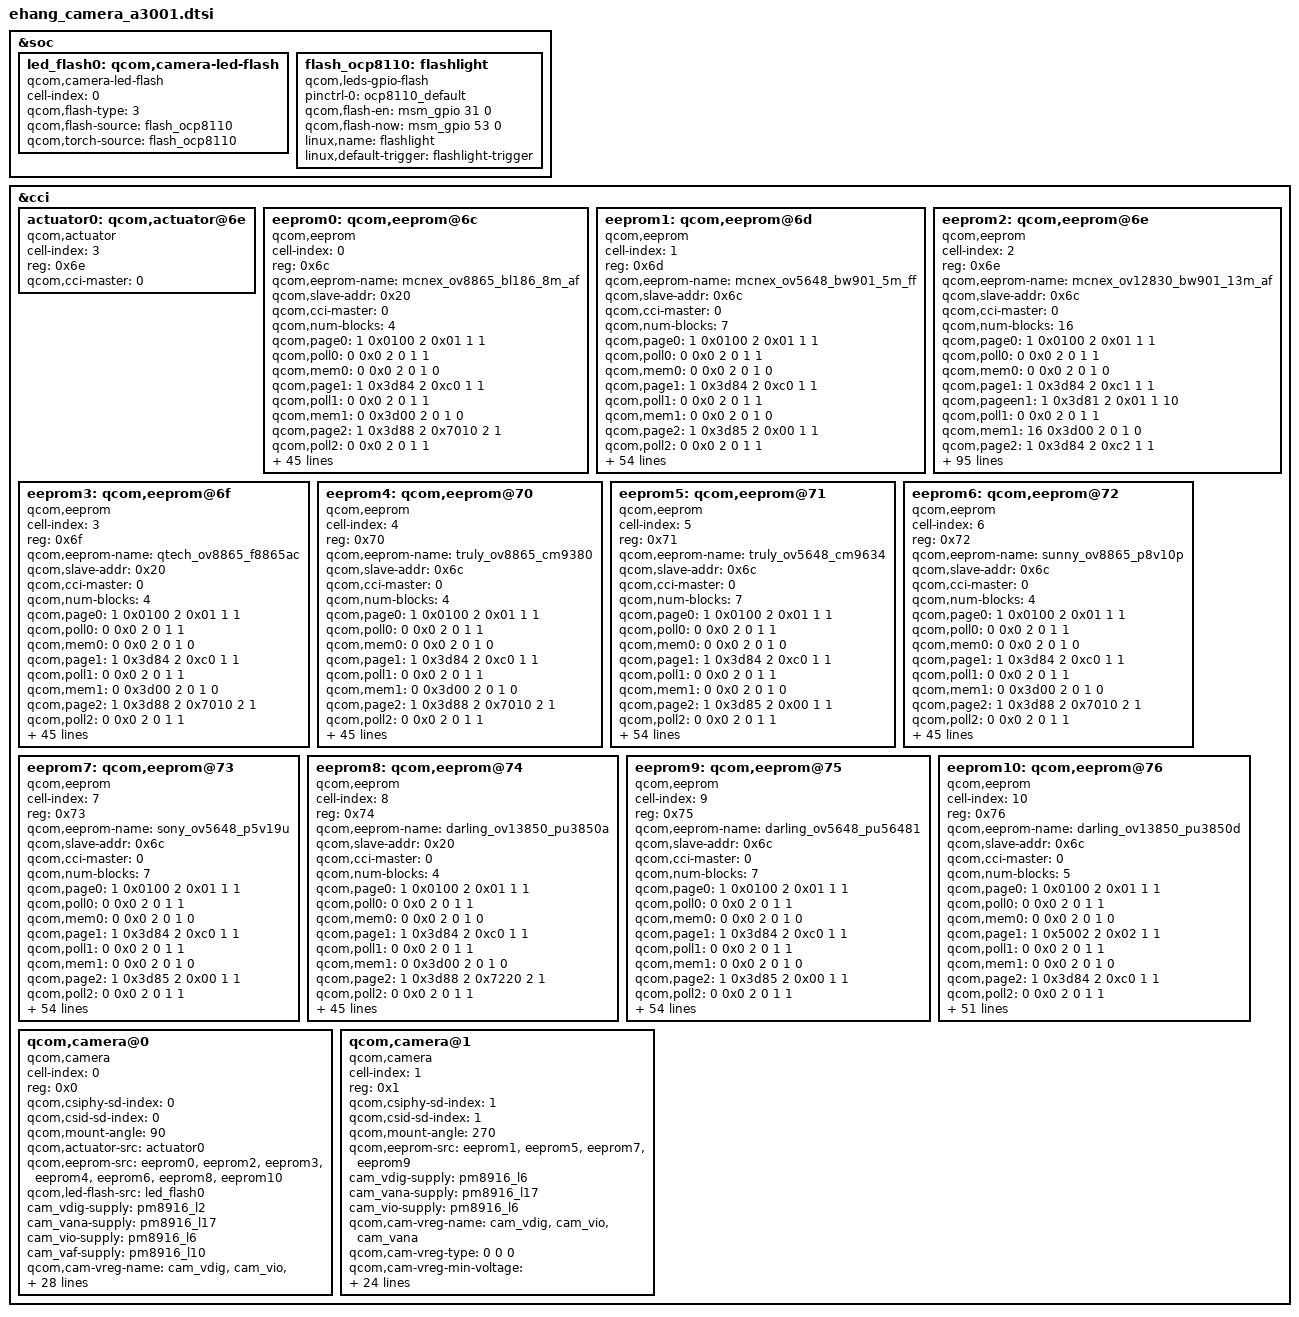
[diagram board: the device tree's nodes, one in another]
/*
 * Copyright (c) 2014, The Linux Foundation. All rights reserved.
 *
 * This program is free software; you can redistribute it and/or modify
 * it under the terms of the GNU General Public License version 2 and
 * only version 2 as published by the Free Software Foundation.
 *
 * This program is distributed in the hope that it will be useful,
 * but WITHOUT ANY WARRANTY; without even the implied warranty of
 * MERCHANTABILITY or FITNESS FOR A PARTICULAR PURPOSE.  See the
 * GNU General Public License for more details.
 */

&soc {
	/*
	i2c@78b9000 {
		led_flash0:sgm,led-flash@60 {
			cell-index = <0>;
			reg = <0x60>;
			compatible = "sgm,led-flash";
			label = "sgm3780";
			qcom,slave-id = <0x60 0x00 0x0011>;
			gpios = <&msm_gpio 31 0>,
			        <&msm_gpio 86 0>;
			qcom,gpio-flash-en = <0>;
			qcom,gpio-flash-now = <1>;
			qcom,gpio-req-tbl-num = <0 1>;
			qcom,gpio-req-tbl-flags = <0 0>;
			qcom,gpio-req-tbl-label = "FLASH_EN",
			                          "FLASH_NOW";					  
		};
	};*/	

	led_flash0: qcom,camera-led-flash {
		cell-index = <0>;
		compatible = "qcom,camera-led-flash";
		qcom,flash-type = <3>;
		qcom,flash-source = <&flash_ocp8110>;
		qcom,torch-source = <&flash_ocp8110>;
	};
	
	/*led_flash0: qcom,led-flash@0 {
		cell-index = <0>;
		reg = <0x66>;
		qcom,slave-id = <0x66 0x00 0x0011>;
		compatible = "qcom,led-flash1";
		label = "bd7710";
		qcom,flash-type = <1>;
		qcom,gpio-no-mux = <0>;
		qcom,enable_pinctrl;
		pinctrl-names = "cam_flash_default", "cam_flash_suspend";
		pinctrl-0 = <&cam_sensor_flash_default>;
		pinctrl-1 = <&cam_sensor_flash_sleep>;
		gpios = <&msm_gpio 36 0>,
			<&msm_gpio 32 0>,
			<&msm_gpio 31 0>;
		qcom,gpio-flash-reset = <0>;
		qcom,gpio-flash-en = <1>;
		qcom,gpio-flash-now = <2>;
		qcom,gpio-req-tbl-num = <0 1 2>;
		qcom,gpio-req-tbl-flags = <0 0 0>;
		qcom,gpio-req-tbl-label = "FLASH_RST",
			"FLASH_EN",
			"FLASH_NOW";
		qcom,cci-master = <0>;
	};*/
	
	flash_ocp8110:flashlight {
		compatible = "qcom,leds-gpio-flash";
		status = "okay";
		pinctrl-names = "ocp8110_default";
		pinctrl-0 = <&ocp8110_default>;
		qcom,flash-en = <&msm_gpio 31 0>;
		qcom,flash-now = <&msm_gpio 53 0>;
		linux,name = "flashlight";
		linux,default-trigger = "flashlight-trigger";
	};
};

&cci {

	actuator0: qcom,actuator@6e {
		cell-index = <3>;
		reg = <0x6e>;
		compatible = "qcom,actuator";
		qcom,cci-master = <0>;
	};
	
	eeprom0: qcom,eeprom@6c {
		cell-index = <0>;
		reg = <0x6c>;
		qcom,eeprom-name = "mcnex_ov8865_bl186_8m_af";
		compatible = "qcom,eeprom";
		qcom,slave-addr = <0x20>;
		qcom,cci-master = <0>;
		qcom,num-blocks = <4>;
		qcom,page0 = <1 0x0100 2 0x01 1 1>;
		qcom,poll0 = <0 0x0 2 0 1 1>;
		qcom,mem0 = <0 0x0 2 0 1 0>;
		qcom,page1 = <1 0x3d84 2 0xc0 1 1>;
		qcom,poll1 = <0 0x0 2 0 1 1>;
		qcom,mem1 = <0 0x3d00 2 0 1 0>;
		qcom,page2 = <1 0x3d88 2 0x7010 2 1>;
		qcom,poll2 = <0 0x0 2 0 1 1>;
		qcom,mem2 = <0 0x3d00 2 0 1 0>;
		qcom,page3 = <1 0x3d8A 2 0x70F4 2 1>;
		qcom,pageen3 = <1 0x3d81 2 0x01 1 10>;
		qcom,poll3 = <0 0x0 2 0 1 1>;
		qcom,mem3 = <228 0x7010 2 0 1 1>;
	
		cam_vdig-supply = <&pm8916_l2>;
		cam_vana-supply = <&pm8916_l17>;
		cam_vio-supply = <&pm8916_l6>;
		qcom,cam-vreg-name = "cam_vdig","cam_vana", "cam_vio";
		qcom,cam-vreg-type = <0 0 0>;
		qcom,cam-vreg-min-voltage = <1200000 2850000 1800000>;
		qcom,cam-vreg-max-voltage = <1200000 2850000 1800000>;
		qcom,cam-vreg-op-mode = <200000 80000 80000>;	
		pinctrl-names = "cam_default", "cam_suspend";
		pinctrl-0 = <&cam_sensor_mclk0_default
		             &cam_sensor_rear_default>;
		pinctrl-1 = <&cam_sensor_mclk0_sleep &cam_sensor_rear_sleep>;		
		qcom,gpio-no-mux = <0>;	
		gpios = <&msm_gpio 26 0>,
		        <&msm_gpio 35 0>,
		        <&msm_gpio 34 0>,
		        <&msm_gpio 121 0>;
		qcom,gpio-reset = <1>;
		qcom,gpio-standby = <2>;
		qcom,gpio-vana = <3>;
		qcom,gpio-req-tbl-num = <0 1 2 3>;
		qcom,gpio-req-tbl-flags = <1 0 0 0>;
		qcom,gpio-req-tbl-label = "CAMIF_MCLK",
					  "CAM_RESET",
					  "CAM_STANDBY",
					  "CAM_VANA";
		qcom,cam-power-seq-type = "sensor_vreg",
		                          "sensor_vreg",
					  "sensor_gpio",
					  "sensor_vreg",
					  "sensor_gpio",
					  "sensor_gpio",
					  "sensor_gpio",
					  "sensor_gpio",
					  "sensor_clk",		
					  "sensor_i2c_mux";
		qcom,cam-power-seq-val = "cam_vio",
		                         "cam_vana",
					 "sensor_gpio_vana",
					 "cam_vdig",
					 "sensor_gpio_standby",
					 "sensor_gpio_reset",
					 "sensor_gpio_standby",
					 "sensor_gpio_reset",
					 "sensor_cam_mclk",
					 "none";
		qcom,cam-power-seq-cfg-val = <0 0 1 0 0 0 1 1 23880000 0>;
		qcom,cam-power-seq-delay = <1 1 5 1 1 5 5 10 10 0>;
		clocks = <&clock_gcc clk_mclk0_clk_src>,
		         <&clock_gcc clk_gcc_camss_mclk0_clk>;
		clock-names = "cam_src_clk", "cam_clk";
	};
	eeprom1: qcom,eeprom@6d {
		cell-index = <1>;
		reg = <0x6d>;
		qcom,eeprom-name = "mcnex_ov5648_bw901_5m_ff";
		compatible = "qcom,eeprom";
		qcom,slave-addr = <0x6c>;
		qcom,cci-master = <0>;
		qcom,num-blocks = <7>;
		qcom,page0 = <1 0x0100 2 0x01 1 1>;
		qcom,poll0 = <0 0x0 2 0 1 1>;
		qcom,mem0 = <0 0x0 2 0 1 0>;
		qcom,page1 = <1 0x3d84 2 0xc0 1 1>;
		qcom,poll1 = <0 0x0 2 0 1 1>;
		qcom,mem1 = <0 0x0 2 0 1 0>;
		qcom,page2 = <1 0x3d85 2 0x00 1 1>;
		qcom,poll2 = <0 0x0 2 0 1 1>;
		qcom,mem2 = <0 0x0 2 0 1 0>;
		qcom,page3 = <1 0x3d86 2 0x0f 1 1>;
		qcom,pageen3 = <1 0x3d81 2 0x01 1 10>;
		qcom,poll3 = <0 0x0 2 0 1 1>;
		qcom,mem3 = <16 0x3d00 2 0 1 0>;
		qcom,page4 = <1 0x3d84 2 0xc0 1 1>;
		qcom,poll4 = <0 0x0 2 0 1 1>;
		qcom,mem4 = <0 0x0 2 0 1 0>;
		qcom,page5 = <1 0x3d85 2 0x10 1 1>;
		qcom,poll5 = <0 0x0 2 0 1 1>;
		qcom,mem5 = <0 0x0 2 0 1 0>;
		qcom,page6 = <1 0x3d86 2 0x1f 1 1>;
		qcom,pageen6 = <1 0x3d81 2 0x01 1 10>;
		qcom,poll6 = <0 0x0 2 0 1 1>;
		qcom,mem6 = <16 0x3d00 2 0 1 0>;	
		cam_vdig-supply = <&pm8916_l6>;
		cam_vana-supply = <&pm8916_l17>;
		cam_vio-supply = <&pm8916_l6>;
		qcom,cam-vreg-name = "cam_vdig","cam_vio", "cam_vana";
		qcom,cam-vreg-type = <0 0 0>;
		qcom,cam-vreg-min-voltage = <1800000 1800000 2850000>;
		qcom,cam-vreg-max-voltage = <1800000 1800000 2850000>;
		qcom,cam-vreg-op-mode = <150000 150000 150000>;	
		pinctrl-names = "cam_default", "cam_suspend";
		pinctrl-0 = <&cam_sensor_mclk1_default &cam_sensor_front_default>;
		pinctrl-1 = <&cam_sensor_mclk1_sleep &cam_sensor_front_sleep>;
		
		gpios = <&msm_gpio 27 0>,
			<&msm_gpio 28 0>,
			<&msm_gpio 33 0>,			
			<&msm_gpio 121 0>;
		qcom,gpio-reset = <1>;
		qcom,gpio-standby = <2>;		
		qcom,gpio-vana = <3>;			
		qcom,gpio-req-tbl-num = <0 1 2 3>;
		qcom,gpio-req-tbl-flags = <1 0 0 0>;
		qcom,gpio-req-tbl-label = "CAMIF_MCLK",
			                  "CAM_RESET",
			                  "CAM_STANDBY",	
			                  "CAM_VANA";			
		qcom,cam-power-seq-type = "sensor_vreg",
		                          "sensor_vreg",
					  "sensor_gpio",
					  "sensor_vreg",
					  "sensor_gpio",
					  "sensor_gpio",
					  "sensor_gpio",
					  "sensor_gpio",
					  "sensor_clk",		
					  "sensor_i2c_mux";
		qcom,cam-power-seq-val =  "cam_vio",
		                          "cam_vana",
					  "sensor_gpio_vana",
					  "cam_vdig",
					  "sensor_gpio_standby",
					  "sensor_gpio_reset",
					  "sensor_gpio_standby",
					  "sensor_gpio_reset",
					  "sensor_cam_mclk",
					  "none";
		qcom,cam-power-seq-cfg-val = <0 0 1 0 0 0 1 1 23880000 0>;
		qcom,cam-power-seq-delay = <1 1 5 1 1 5 5 10 10 0>;
		clocks = <&clock_gcc clk_mclk1_clk_src>,
		         <&clock_gcc clk_gcc_camss_mclk1_clk>;
		clock-names = "cam_src_clk", "cam_clk";
	};
	eeprom2: qcom,eeprom@6e{
		cell-index = <2>;
		reg = <0x6e>;
		qcom,eeprom-name = "mcnex_ov12830_bw901_13m_af";
		compatible = "qcom,eeprom";
		qcom,slave-addr = <0x6c>;
		qcom,cci-master = <0>;
		qcom,num-blocks = <16>;
		qcom,page0 = <1 0x0100 2 0x01 1 1>;
		qcom,poll0 = <0 0x0 2 0 1 1>;
		qcom,mem0 = <0 0x0 2 0 1 0>;
		qcom,page1 = <1 0x3d84 2 0xc1 1 1>;
		qcom,pageen1 = <1 0x3d81 2 0x01 1 10>;
		qcom,poll1 = <0 0x0 2 0 1 1>;
		qcom,mem1 = <16 0x3d00 2 0 1 0>;
		qcom,page2 = <1 0x3d84 2 0xc2 1 1>;
		qcom,pageen2 = <1 0x3d81 2 0x01 1 10>;
		qcom,poll2 = <0 0x0 2 0 1 1>;
		qcom,mem2 = <16 0x3d00 2 0 1 0>;
		qcom,page3 = <1 0x3d84 2 0xc3 1 1>;
		qcom,pageen3 = <1 0x3d81 2 0x01 1 10>;
		qcom,poll3 = <0 0x0 2 0 1 1>;
		qcom,mem3 = <16 0x3d00 2 0 1 0>;
		qcom,page4 = <1 0x3d84 2 0xc4 1 1>;
		qcom,pageen4 = <1 0x3d81 2 0x01 1 10>;
		qcom,poll4 = <0 0x0 2 0 1 1>;
		qcom,mem4 = <16 0x3d00 2 0 1 0>;
		qcom,page5 = <1 0x3d84 2 0xc5 1 1>;
		qcom,pageen5 = <1 0x3d81 2 0x01 1 10>;
		qcom,poll5 = <0 0x0 2 0 1 1>;
		qcom,mem5 = <16 0x3d00 2 0 1 0>;
		qcom,page6 = <1 0x3d84 2 0xc6 1 1>;
		qcom,pageen6 = <1 0x3d81 2 0x01 1 10>;
		qcom,poll6 = <0 0x0 2 0 1 1>;
		qcom,mem6 = <16 0x3d00 2 0 1 0>;
		qcom,page7 = <1 0x3d84 2 0xc7 1 1>;
		qcom,pageen7 = <1 0x3d81 2 0x01 1 10>;
		qcom,poll7 = <0 0x0 2 0 1 1>;
		qcom,mem7 = <16 0x3d00 2 0 1 0>;
		qcom,page8 = <1 0x3d84 2 0xc8 1 1>;
		qcom,pageen8 = <1 0x3d81 2 0x01 1 10>;
		qcom,poll8 = <0 0x0 2 0 1 1>;
		qcom,mem8 = <16 0x3d00 2 0 1 0>;
		qcom,page9 = <1 0x3d84 2 0xc9 1 1>;
		qcom,pageen9 = <1 0x3d81 2 0x01 1 10>;
		qcom,poll9 = <0 0x0 2 0 1 1>;
		qcom,mem9 = <16 0x3d00 2 0 1 0>;
		qcom,page10 = <1 0x3d84 2 0xca 1 1>;
		qcom,pageen10 = <1 0x3d81 2 0x01 1 10>;
		qcom,poll10 = <0 0x0 2 0 1 1>;
		qcom,mem10 = <16 0x3d00 2 0 1 0>;
		qcom,page11 = <1 0x3d84 2 0xcb 1 1>;
		qcom,pageen11 = <1 0x3d81 2 0x01 1 10>;
		qcom,poll11 = <0 0x0 2 0 1 1>;
		qcom,mem11 = <16 0x3d00 2 0 1 0>;
		qcom,page12 = <1 0x3d84 2 0xcc 1 1>;
		qcom,pageen12 = <1 0x3d81 2 0x01 1 10>;
		qcom,poll12 = <0 0x0 2 0 1 1>;
		qcom,mem12 = <16 0x3d00 2 0 1 0>;
		qcom,page13 = <1 0x3d84 2 0xcd 1 1>;
		qcom,pageen13 = <1 0x3d81 2 0x01 1 10>;
		qcom,poll13 = <0 0x0 2 0 1 1>;
		qcom,mem13 = <16 0x3d00 2 0 1 0>;
		qcom,page14 = <1 0x3d84 2 0xce 1 1>;
		qcom,pageen14 = <1 0x3d81 2 0x01 1 10>;
		qcom,poll14 = <0 0x0 2 0 1 1>;
		qcom,mem14 = <16 0x3d00 2 0 1 0>;
		qcom,page15 = <1 0x3d84 2 0xcf 1 1>;
		qcom,pageen15 = <1 0x3d81 2 0x01 1 10>;
		qcom,poll15 = <0 0x0 2 0 1 1>;
		qcom,mem15 = <16 0x3d00 2 0 1 0>;	
		cam_vdig-supply = <&pm8916_l2>;
		cam_vana-supply = <&pm8916_l17>;
		cam_vio-supply = <&pm8916_l6>;
		qcom,cam-vreg-name = "cam_vdig","cam_vana", "cam_vio";
		qcom,cam-vreg-type = <0 0 0>;
		qcom,cam-vreg-min-voltage = <1200000 2850000 1800000>;
		qcom,cam-vreg-max-voltage = <1200000 2850000 1800000>;
		qcom,cam-vreg-op-mode = <200000 80000 80000>;	
		pinctrl-names = "cam_default", "cam_suspend";
		pinctrl-0 = <&cam_sensor_mclk0_default
		             &cam_sensor_rear_default>;
		pinctrl-1 = <&cam_sensor_mclk0_sleep &cam_sensor_rear_sleep>;		
		qcom,gpio-no-mux = <0>;	
		gpios = <&msm_gpio 26 0>,
		        <&msm_gpio 35 0>,
		        <&msm_gpio 34 0>,
		        <&msm_gpio 121 0>;
		qcom,gpio-reset = <1>;
		qcom,gpio-standby = <2>;
		qcom,gpio-vana = <3>;
		qcom,gpio-req-tbl-num = <0 1 2 3>;
		qcom,gpio-req-tbl-flags = <1 0 0 0>;
		qcom,gpio-req-tbl-label = "CAMIF_MCLK",
					  "CAM_RESET",
					  "CAM_STANDBY",
					  "CAM_VANA";
		qcom,cam-power-seq-type = "sensor_vreg",
		                          "sensor_vreg",
					  "sensor_gpio",
					  "sensor_vreg",
					  "sensor_gpio",
					  "sensor_gpio",
					  "sensor_gpio",
					  "sensor_gpio",
					  "sensor_clk",		
					  "sensor_i2c_mux";
		qcom,cam-power-seq-val = "cam_vio",
		                         "cam_vana",
					 "sensor_gpio_vana",
					 "cam_vdig",
					 "sensor_gpio_standby",
					 "sensor_gpio_reset",
					 "sensor_gpio_standby",
					 "sensor_gpio_reset",
					 "sensor_cam_mclk",
					 "none";
		qcom,cam-power-seq-cfg-val = <0 0 1 0 0 0 1 1 23880000 0>;
		qcom,cam-power-seq-delay = <1 1 5 1 1 5 5 10 10 0>;
		clocks = <&clock_gcc clk_mclk0_clk_src>,
		         <&clock_gcc clk_gcc_camss_mclk0_clk>;
		clock-names = "cam_src_clk", "cam_clk";
	};
	
	eeprom3: qcom,eeprom@6f {
		cell-index = <3>;
		reg = <0x6f>;
		qcom,eeprom-name = "qtech_ov8865_f8865ac";
		compatible = "qcom,eeprom";
		qcom,slave-addr = <0x20>;
		qcom,cci-master = <0>;
		qcom,num-blocks = <4>;
		qcom,page0 = <1 0x0100 2 0x01 1 1>;
		qcom,poll0 = <0 0x0 2 0 1 1>;
		qcom,mem0 = <0 0x0 2 0 1 0>;
		qcom,page1 = <1 0x3d84 2 0xc0 1 1>;
		qcom,poll1 = <0 0x0 2 0 1 1>;
		qcom,mem1 = <0 0x3d00 2 0 1 0>;
		qcom,page2 = <1 0x3d88 2 0x7010 2 1>;
		qcom,poll2 = <0 0x0 2 0 1 1>;
		qcom,mem2 = <0 0x3d00 2 0 1 0>;
		qcom,page3 = <1 0x3d8A 2 0x70F4 2 1>;
		qcom,pageen3 = <1 0x3d81 2 0x01 1 10>;
		qcom,poll3 = <0 0x0 2 0 1 1>;
		qcom,mem3 = <228 0x7010 2 0 1 1>;
	
		cam_vdig-supply = <&pm8916_l2>;
		cam_vana-supply = <&pm8916_l17>;
		cam_vio-supply = <&pm8916_l6>;
		qcom,cam-vreg-name = "cam_vdig","cam_vana", "cam_vio";
		qcom,cam-vreg-type = <0 0 0>;
		qcom,cam-vreg-min-voltage = <1200000 2850000 1800000>;
		qcom,cam-vreg-max-voltage = <1200000 2850000 1800000>;
		qcom,cam-vreg-op-mode = <200000 80000 80000>;	
		pinctrl-names = "cam_default", "cam_suspend";
		pinctrl-0 = <&cam_sensor_mclk0_default
		             &cam_sensor_rear_default>;
		pinctrl-1 = <&cam_sensor_mclk0_sleep &cam_sensor_rear_sleep>;		
		qcom,gpio-no-mux = <0>;	
		gpios = <&msm_gpio 26 0>,
		        <&msm_gpio 35 0>,
		        <&msm_gpio 34 0>,
		        <&msm_gpio 121 0>;
		qcom,gpio-reset = <1>;
		qcom,gpio-standby = <2>;
		qcom,gpio-vana = <3>;
		qcom,gpio-req-tbl-num = <0 1 2 3>;
		qcom,gpio-req-tbl-flags = <1 0 0 0>;
		qcom,gpio-req-tbl-label = "CAMIF_MCLK",
					  "CAM_RESET",
					  "CAM_STANDBY",
					  "CAM_VANA";
		qcom,cam-power-seq-type = "sensor_vreg",
		                          "sensor_vreg",
					  "sensor_gpio",
					  "sensor_vreg",
					  "sensor_gpio",
					  "sensor_gpio",
					  "sensor_gpio",
					  "sensor_gpio",
					  "sensor_clk",		
					  "sensor_i2c_mux";
		qcom,cam-power-seq-val = "cam_vio",
		                         "cam_vana",
					 "sensor_gpio_vana",
					 "cam_vdig",
					 "sensor_gpio_standby",
					 "sensor_gpio_reset",
					 "sensor_gpio_standby",
					 "sensor_gpio_reset",
					 "sensor_cam_mclk",
					 "none";
		qcom,cam-power-seq-cfg-val = <0 0 1 0 0 0 1 1 23880000 0>;   
		qcom,cam-power-seq-delay = <1 1 5 1 1 5 5 10 10 0>;
		clocks = <&clock_gcc clk_mclk0_clk_src>,
		         <&clock_gcc clk_gcc_camss_mclk0_clk>;
		clock-names = "cam_src_clk", "cam_clk";
	};
	eeprom4: qcom,eeprom@70 {
		cell-index = <4>;
		reg = <0x70>;
		qcom,eeprom-name = "truly_ov8865_cm9380";
		compatible = "qcom,eeprom";
		qcom,slave-addr = <0x6c>;	    
		qcom,cci-master = <0>;
		qcom,num-blocks = <4>;
		qcom,page0 = <1 0x0100 2 0x01 1 1>;
		qcom,poll0 = <0 0x0 2 0 1 1>;
		qcom,mem0 = <0 0x0 2 0 1 0>;
		qcom,page1 = <1 0x3d84 2 0xc0 1 1>;
		qcom,poll1 = <0 0x0 2 0 1 1>;
		qcom,mem1 = <0 0x3d00 2 0 1 0>;
		qcom,page2 = <1 0x3d88 2 0x7010 2 1>;
		qcom,poll2 = <0 0x0 2 0 1 1>;
		qcom,mem2 = <0 0x3d00 2 0 1 0>;
		qcom,page3 = <1 0x3d8A 2 0x70F4 2 1>;
		qcom,pageen3 = <1 0x3d81 2 0x01 1 10>;
		qcom,poll3 = <0 0x0 2 0 1 1>;
		qcom,mem3 = <228 0x7010 2 0 1 1>;		
		cam_vdig-supply = <&pm8916_l2>;
		cam_vana-supply = <&pm8916_l17>;
		cam_vio-supply = <&pm8916_l6>;
		qcom,cam-vreg-name = "cam_vdig","cam_vana", "cam_vio";
		qcom,cam-vreg-type = <0 0 0>;
		qcom,cam-vreg-min-voltage = <1200000 2850000 1800000>;
		qcom,cam-vreg-max-voltage = <1200000 2850000 1800000>;
		qcom,cam-vreg-op-mode = <200000 80000 80000>;	
		pinctrl-names = "cam_default", "cam_suspend";
		pinctrl-0 = <&cam_sensor_mclk0_default
		             &cam_sensor_rear_default>;
		pinctrl-1 = <&cam_sensor_mclk0_sleep &cam_sensor_rear_sleep>;		
		qcom,gpio-no-mux = <0>;	
		gpios = <&msm_gpio 26 0>,
		        <&msm_gpio 35 0>,
		        <&msm_gpio 34 0>,
		        <&msm_gpio 121 0>;
		qcom,gpio-reset = <1>;
		qcom,gpio-standby = <2>;
		qcom,gpio-vana = <3>;
		qcom,gpio-req-tbl-num = <0 1 2 3>;
		qcom,gpio-req-tbl-flags = <1 0 0 0>;
		qcom,gpio-req-tbl-label = "CAMIF_MCLK",
					  "CAM_RESET",
					  "CAM_STANDBY",
					  "CAM_VANA";
		qcom,cam-power-seq-type = "sensor_vreg",
		                          "sensor_vreg",
					  "sensor_gpio",
					  "sensor_vreg",
					  "sensor_gpio",
					  "sensor_gpio",
					  "sensor_gpio",
					  "sensor_gpio",
					  "sensor_clk",		
					  "sensor_i2c_mux";
		qcom,cam-power-seq-val = "cam_vio",
		                         "cam_vana",
					 "sensor_gpio_vana",
					 "cam_vdig",
					 "sensor_gpio_standby",
					 "sensor_gpio_reset",
					 "sensor_gpio_standby",
					 "sensor_gpio_reset",
					 "sensor_cam_mclk",
					 "none";
		qcom,cam-power-seq-cfg-val = <0 0 1 0 0 0 1 1 23880000 0>;
		qcom,cam-power-seq-delay = <1 1 5 1 1 5 5 10 10 0>;
		clocks = <&clock_gcc clk_mclk0_clk_src>,
		         <&clock_gcc clk_gcc_camss_mclk0_clk>;
		clock-names = "cam_src_clk", "cam_clk";
	};
	eeprom5: qcom,eeprom@71 {
		cell-index = <5>;
		reg = <0x71>;
		qcom,eeprom-name = "truly_ov5648_cm9634";
		compatible = "qcom,eeprom";
		qcom,slave-addr = <0x6c>;
		qcom,cci-master = <0>;
		qcom,num-blocks = <7>;
		qcom,page0 = <1 0x0100 2 0x01 1 1>;
		qcom,poll0 = <0 0x0 2 0 1 1>;
		qcom,mem0 = <0 0x0 2 0 1 0>;
		qcom,page1 = <1 0x3d84 2 0xc0 1 1>;
		qcom,poll1 = <0 0x0 2 0 1 1>;
		qcom,mem1 = <0 0x0 2 0 1 0>;
		qcom,page2 = <1 0x3d85 2 0x00 1 1>;
		qcom,poll2 = <0 0x0 2 0 1 1>;
		qcom,mem2 = <0 0x0 2 0 1 0>;
		qcom,page3 = <1 0x3d86 2 0x0f 1 1>;
		qcom,pageen3 = <1 0x3d81 2 0x01 1 10>;
		qcom,poll3 = <0 0x0 2 0 1 1>;
		qcom,mem3 = <16 0x3d00 2 0 1 0>;
		qcom,page4 = <1 0x3d84 2 0xc0 1 1>;
		qcom,poll4 = <0 0x0 2 0 1 1>;
		qcom,mem4 = <0 0x0 2 0 1 0>;
		qcom,page5 = <1 0x3d85 2 0x10 1 1>;
		qcom,poll5 = <0 0x0 2 0 1 1>;
		qcom,mem5 = <0 0x0 2 0 1 0>;
		qcom,page6 = <1 0x3d86 2 0x1f 1 1>;
		qcom,pageen6 = <1 0x3d81 2 0x01 1 10>;
		qcom,poll6 = <0 0x0 2 0 1 1>;
		qcom,mem6 = <16 0x3d00 2 0 1 0>;
		cam_vdig-supply = <&pm8916_l6>;
		cam_vana-supply = <&pm8916_l17>;
		cam_vio-supply = <&pm8916_l6>;
		qcom,cam-vreg-name = "cam_vdig","cam_vio", "cam_vana";
		qcom,cam-vreg-type = <0 0 0>;
		qcom,cam-vreg-min-voltage = <1800000 1800000 2850000>;
		qcom,cam-vreg-max-voltage = <1800000 1800000 2850000>;
		qcom,cam-vreg-op-mode = <150000 150000 150000>;	
		pinctrl-names = "cam_default", "cam_suspend";
		pinctrl-0 = <&cam_sensor_mclk1_default &cam_sensor_front_default>;
		pinctrl-1 = <&cam_sensor_mclk1_sleep &cam_sensor_front_sleep>;
		
		gpios = <&msm_gpio 27 0>,
			<&msm_gpio 28 0>,
			<&msm_gpio 33 0>,			
			<&msm_gpio 121 0>;
		qcom,gpio-reset = <1>;
		qcom,gpio-standby = <2>;		
		qcom,gpio-vana = <3>;			
		qcom,gpio-req-tbl-num = <0 1 2 3>;
		qcom,gpio-req-tbl-flags = <1 0 0 0>;
		qcom,gpio-req-tbl-label = "CAMIF_MCLK",
			                  "CAM_RESET",
			                  "CAM_STANDBY",	
			                  "CAM_VANA";			
		qcom,cam-power-seq-type = "sensor_vreg",
		                          "sensor_vreg",
					  "sensor_gpio",
					  "sensor_vreg",
					  "sensor_gpio",
					  "sensor_gpio",
					  "sensor_gpio",
					  "sensor_gpio",
					  "sensor_clk",		
					  "sensor_i2c_mux";
		qcom,cam-power-seq-val =  "cam_vio",
		                          "cam_vana",
					  "sensor_gpio_vana",
					  "cam_vdig",
					  "sensor_gpio_standby",
					  "sensor_gpio_reset",
					  "sensor_gpio_standby",
					  "sensor_gpio_reset",
					  "sensor_cam_mclk",
					  "none";
		qcom,cam-power-seq-cfg-val = <0 0 1 0 0 0 1 1 23880000 0>;
		qcom,cam-power-seq-delay = <1 1 5 1 1 5 5 10 10 0>;
		clocks = <&clock_gcc clk_mclk1_clk_src>,
		         <&clock_gcc clk_gcc_camss_mclk1_clk>;
		clock-names = "cam_src_clk", "cam_clk";
	};
	eeprom6: qcom,eeprom@72 {
		cell-index = <6>;
		reg = <0x72>;
		qcom,eeprom-name = "sunny_ov8865_p8v10p";
		compatible = "qcom,eeprom";
		qcom,slave-addr = <0x6c>;	    
		qcom,cci-master = <0>;
		qcom,num-blocks = <4>;
		qcom,page0 = <1 0x0100 2 0x01 1 1>;
		qcom,poll0 = <0 0x0 2 0 1 1>;
		qcom,mem0 = <0 0x0 2 0 1 0>;
		qcom,page1 = <1 0x3d84 2 0xc0 1 1>;
		qcom,poll1 = <0 0x0 2 0 1 1>;
		qcom,mem1 = <0 0x3d00 2 0 1 0>;
		qcom,page2 = <1 0x3d88 2 0x7010 2 1>;
		qcom,poll2 = <0 0x0 2 0 1 1>;
		qcom,mem2 = <0 0x3d00 2 0 1 0>;
		qcom,page3 = <1 0x3d8A 2 0x70F4 2 1>;
		qcom,pageen3 = <1 0x3d81 2 0x01 1 10>;
		qcom,poll3 = <0 0x0 2 0 1 1>;
		qcom,mem3 = <228 0x7010 2 0 1 1>;		
		cam_vdig-supply = <&pm8916_l2>;
		cam_vana-supply = <&pm8916_l17>;
		cam_vio-supply = <&pm8916_l6>;
		qcom,cam-vreg-name = "cam_vdig","cam_vana", "cam_vio";
		qcom,cam-vreg-type = <0 0 0>;
		qcom,cam-vreg-min-voltage = <1200000 2850000 1800000>;
		qcom,cam-vreg-max-voltage = <1200000 2850000 1800000>;
		qcom,cam-vreg-op-mode = <200000 80000 80000>;	
		pinctrl-names = "cam_default", "cam_suspend";
		pinctrl-0 = <&cam_sensor_mclk0_default
		             &cam_sensor_rear_default>;
		pinctrl-1 = <&cam_sensor_mclk0_sleep &cam_sensor_rear_sleep>;		
		qcom,gpio-no-mux = <0>;	
		gpios = <&msm_gpio 26 0>,
		        <&msm_gpio 35 0>,
		        <&msm_gpio 34 0>,
		        <&msm_gpio 121 0>;
		qcom,gpio-reset = <1>;
		qcom,gpio-standby = <2>;
		qcom,gpio-vana = <3>;
		qcom,gpio-req-tbl-num = <0 1 2 3>;
		qcom,gpio-req-tbl-flags = <1 0 0 0>;
		qcom,gpio-req-tbl-label = "CAMIF_MCLK",
					  "CAM_RESET",
					  "CAM_STANDBY",
					  "CAM_VANA";
		qcom,cam-power-seq-type = "sensor_vreg",
		                          "sensor_vreg",
					  "sensor_gpio",
					  "sensor_vreg",
					  "sensor_gpio",
					  "sensor_gpio",
					  "sensor_gpio",
					  "sensor_gpio",
					  "sensor_clk",		
					  "sensor_i2c_mux";
		qcom,cam-power-seq-val = "cam_vio",
		                         "cam_vana",
					 "sensor_gpio_vana",
					 "cam_vdig",
					 "sensor_gpio_standby",
					 "sensor_gpio_reset",
					 "sensor_gpio_standby",
					 "sensor_gpio_reset",
					 "sensor_cam_mclk",
					 "none";
		qcom,cam-power-seq-cfg-val = <0 0 1 0 0 0 1 1 23880000 0>;
		qcom,cam-power-seq-delay = <1 1 5 1 1 5 5 10 10 0>;
		clocks = <&clock_gcc clk_mclk0_clk_src>,
		         <&clock_gcc clk_gcc_camss_mclk0_clk>;
		clock-names = "cam_src_clk", "cam_clk";
	};
	eeprom7: qcom,eeprom@73 {
		cell-index = <7>;
		reg = <0x73>;
		qcom,eeprom-name = "sony_ov5648_p5v19u";
		compatible = "qcom,eeprom";
		qcom,slave-addr = <0x6c>;
		qcom,cci-master = <0>;
		qcom,num-blocks = <7>;
		qcom,page0 = <1 0x0100 2 0x01 1 1>;
		qcom,poll0 = <0 0x0 2 0 1 1>;
		qcom,mem0 = <0 0x0 2 0 1 0>;
		qcom,page1 = <1 0x3d84 2 0xc0 1 1>;
		qcom,poll1 = <0 0x0 2 0 1 1>;
		qcom,mem1 = <0 0x0 2 0 1 0>;
		qcom,page2 = <1 0x3d85 2 0x00 1 1>;
		qcom,poll2 = <0 0x0 2 0 1 1>;
		qcom,mem2 = <0 0x0 2 0 1 0>;
		qcom,page3 = <1 0x3d86 2 0x0f 1 1>;
		qcom,pageen3 = <1 0x3d81 2 0x01 1 10>;
		qcom,poll3 = <0 0x0 2 0 1 1>;
		qcom,mem3 = <16 0x3d00 2 0 1 0>;
		qcom,page4 = <1 0x3d84 2 0xc0 1 1>;
		qcom,poll4 = <0 0x0 2 0 1 1>;
		qcom,mem4 = <0 0x0 2 0 1 0>;
		qcom,page5 = <1 0x3d85 2 0x10 1 1>;
		qcom,poll5 = <0 0x0 2 0 1 1>;
		qcom,mem5 = <0 0x0 2 0 1 0>;
		qcom,page6 = <1 0x3d86 2 0x1f 1 1>;
		qcom,pageen6 = <1 0x3d81 2 0x01 1 10>;
		qcom,poll6 = <0 0x0 2 0 1 1>;
		qcom,mem6 = <16 0x3d00 2 0 1 0>;
		cam_vdig-supply = <&pm8916_l6>;
		cam_vana-supply = <&pm8916_l17>;
		cam_vio-supply = <&pm8916_l6>;
		qcom,cam-vreg-name = "cam_vdig","cam_vio", "cam_vana";
		qcom,cam-vreg-type = <0 0 0>;
		qcom,cam-vreg-min-voltage = <1800000 1800000 2850000>;
		qcom,cam-vreg-max-voltage = <1800000 1800000 2850000>;
		qcom,cam-vreg-op-mode = <150000 150000 150000>;	
		pinctrl-names = "cam_default", "cam_suspend";
		pinctrl-0 = <&cam_sensor_mclk1_default &cam_sensor_front_default>;
		pinctrl-1 = <&cam_sensor_mclk1_sleep &cam_sensor_front_sleep>;
		
		gpios = <&msm_gpio 27 0>,
			<&msm_gpio 28 0>,
			<&msm_gpio 33 0>,			
			<&msm_gpio 121 0>;
		qcom,gpio-reset = <1>;
		qcom,gpio-standby = <2>;		
		qcom,gpio-vana = <3>;			
		qcom,gpio-req-tbl-num = <0 1 2 3>;
		qcom,gpio-req-tbl-flags = <1 0 0 0>;
		qcom,gpio-req-tbl-label = "CAMIF_MCLK",
			                  "CAM_RESET",
			                  "CAM_STANDBY",	
			                  "CAM_VANA";			
		qcom,cam-power-seq-type = "sensor_vreg",
		                          "sensor_vreg",
					  "sensor_gpio",
					  "sensor_vreg",
					  "sensor_gpio",
					  "sensor_gpio",
					  "sensor_gpio",
					  "sensor_gpio",
					  "sensor_clk",		
					  "sensor_i2c_mux";
		qcom,cam-power-seq-val =  "cam_vio",
		                          "cam_vana",
					  "sensor_gpio_vana",
					  "cam_vdig",
					  "sensor_gpio_standby",
					  "sensor_gpio_reset",
					  "sensor_gpio_standby",
					  "sensor_gpio_reset",
					  "sensor_cam_mclk",
					  "none";
		qcom,cam-power-seq-cfg-val = <0 0 1 0 0 0 1 1 23880000 0>;
		qcom,cam-power-seq-delay = <1 1 5 1 1 5 5 10 10 0>;
		clocks = <&clock_gcc clk_mclk1_clk_src>,
		         <&clock_gcc clk_gcc_camss_mclk1_clk>;
		clock-names = "cam_src_clk", "cam_clk";
	};
	eeprom8: qcom,eeprom@74 {
		cell-index = <8>;
		reg = <0x74>;
		qcom,eeprom-name = "darling_ov13850_pu3850a";
		compatible = "qcom,eeprom";
		qcom,slave-addr = <0x20>;
		qcom,cci-master = <0>;
		qcom,num-blocks = <4>;
		qcom,page0 = <1 0x0100 2 0x01 1 1>;
		qcom,poll0 = <0 0x0 2 0 1 1>;
		qcom,mem0 = <0 0x0 2 0 1 0>;
		qcom,page1 = <1 0x3d84 2 0xc0 1 1>;
		qcom,poll1 = <0 0x0 2 0 1 1>;
		qcom,mem1 = <0 0x3d00 2 0 1 0>;
		qcom,page2 = <1 0x3d88 2 0x7220 2 1>;
		qcom,poll2 = <0 0x0 2 0 1 1>;
		qcom,mem2 = <0 0x3d00 2 0 1 0>;
		qcom,page3 = <1 0x3d8a 2 0x73be 2 1>;
		qcom,pageen3 = <1 0x3d81 2 0x01 1 5>;
		qcom,poll3 = <0 0x0 2 0 1 1>;
		qcom,mem3 = <414 0x7220 2 0 1 1>;
	
		cam_vdig-supply = <&pm8916_l2>;
		cam_vana-supply = <&pm8916_l17>;
		cam_vio-supply = <&pm8916_l6>;
		qcom,cam-vreg-name = "cam_vdig","cam_vana", "cam_vio";
		qcom,cam-vreg-type = <0 0 0>;
		qcom,cam-vreg-min-voltage = <1200000 2850000 1800000>;
		qcom,cam-vreg-max-voltage = <1200000 2850000 1800000>;
		qcom,cam-vreg-op-mode = <200000 80000 80000>;	
		pinctrl-names = "cam_default", "cam_suspend";
		pinctrl-0 = <&cam_sensor_mclk0_default
		             &cam_sensor_rear_default>;
		pinctrl-1 = <&cam_sensor_mclk0_sleep &cam_sensor_rear_sleep>;		
		qcom,gpio-no-mux = <0>;	
		gpios = <&msm_gpio 26 0>,
		        <&msm_gpio 35 0>,
		        <&msm_gpio 34 0>,
		        <&msm_gpio 121 0>;
		qcom,gpio-reset = <1>;
		qcom,gpio-standby = <2>;
		qcom,gpio-vana = <3>;
		qcom,gpio-req-tbl-num = <0 1 2 3>;
		qcom,gpio-req-tbl-flags = <1 0 0 0>;
		qcom,gpio-req-tbl-label = "CAMIF_MCLK",
					  "CAM_RESET",
					  "CAM_STANDBY",
					  "CAM_VANA";
		qcom,cam-power-seq-type = "sensor_vreg",
		                          "sensor_vreg",
					  "sensor_gpio",
					  "sensor_vreg",
					  "sensor_gpio",
					  "sensor_gpio",
					  "sensor_gpio",
					  "sensor_gpio",
					  "sensor_clk",		
					  "sensor_i2c_mux";
		qcom,cam-power-seq-val = "cam_vio",
		                         "cam_vana",
					 "sensor_gpio_vana",
					 "cam_vdig",
					 "sensor_gpio_standby",
					 "sensor_gpio_reset",
					 "sensor_gpio_standby",
					 "sensor_gpio_reset",
					 "sensor_cam_mclk",
					 "none";
		qcom,cam-power-seq-cfg-val = <0 0 1 0 0 0 1 1 23880000 0>;   
		qcom,cam-power-seq-delay = <1 1 5 1 1 5 5 10 10 0>;
		clocks = <&clock_gcc clk_mclk0_clk_src>,
		         <&clock_gcc clk_gcc_camss_mclk0_clk>;
		clock-names = "cam_src_clk", "cam_clk";
	};
	eeprom9: qcom,eeprom@75 {
		cell-index = <9>;
		reg = <0x75>;
		qcom,eeprom-name = "darling_ov5648_pu56481";
		compatible = "qcom,eeprom";
		qcom,slave-addr = <0x6c>;
		qcom,cci-master = <0>;
		qcom,num-blocks = <7>;
		qcom,page0 = <1 0x0100 2 0x01 1 1>;
		qcom,poll0 = <0 0x0 2 0 1 1>;
		qcom,mem0 = <0 0x0 2 0 1 0>;
		qcom,page1 = <1 0x3d84 2 0xc0 1 1>;
		qcom,poll1 = <0 0x0 2 0 1 1>;
		qcom,mem1 = <0 0x0 2 0 1 0>;
		qcom,page2 = <1 0x3d85 2 0x00 1 1>;
		qcom,poll2 = <0 0x0 2 0 1 1>;
		qcom,mem2 = <0 0x0 2 0 1 0>;
		qcom,page3 = <1 0x3d86 2 0x0f 1 1>;
		qcom,pageen3 = <1 0x3d81 2 0x01 1 10>;
		qcom,poll3 = <0 0x0 2 0 1 1>;
		qcom,mem3 = <16 0x3d00 2 0 1 0>;
		qcom,page4 = <1 0x3d84 2 0xc0 1 1>;
		qcom,poll4 = <0 0x0 2 0 1 1>;
		qcom,mem4 = <0 0x0 2 0 1 0>;
		qcom,page5 = <1 0x3d85 2 0x10 1 1>;
		qcom,poll5 = <0 0x0 2 0 1 1>;
		qcom,mem5 = <0 0x0 2 0 1 0>;
		qcom,page6 = <1 0x3d86 2 0x1f 1 1>;
		qcom,pageen6 = <1 0x3d81 2 0x01 1 10>;
		qcom,poll6 = <0 0x0 2 0 1 1>;
		qcom,mem6 = <16 0x3d00 2 0 1 0>;
		cam_vdig-supply = <&pm8916_l6>;
		cam_vana-supply = <&pm8916_l17>;
		cam_vio-supply = <&pm8916_l6>;
		qcom,cam-vreg-name = "cam_vdig","cam_vio", "cam_vana";
		qcom,cam-vreg-type = <0 0 0>;
		qcom,cam-vreg-min-voltage = <1800000 1800000 2850000>;
		qcom,cam-vreg-max-voltage = <1800000 1800000 2850000>;
		qcom,cam-vreg-op-mode = <150000 150000 150000>;	
		pinctrl-names = "cam_default", "cam_suspend";
		pinctrl-0 = <&cam_sensor_mclk1_default &cam_sensor_front_default>;
		pinctrl-1 = <&cam_sensor_mclk1_sleep &cam_sensor_front_sleep>;
		
		gpios = <&msm_gpio 27 0>,
			<&msm_gpio 28 0>,
			<&msm_gpio 33 0>,			
			<&msm_gpio 121 0>;
		qcom,gpio-reset = <1>;
		qcom,gpio-standby = <2>;		
		qcom,gpio-vana = <3>;			
		qcom,gpio-req-tbl-num = <0 1 2 3>;
		qcom,gpio-req-tbl-flags = <1 0 0 0>;
		qcom,gpio-req-tbl-label = "CAMIF_MCLK",
			                  "CAM_RESET",
			                  "CAM_STANDBY",	
			                  "CAM_VANA";			
		qcom,cam-power-seq-type = "sensor_vreg",
		                          "sensor_vreg",
					  "sensor_gpio",
					  "sensor_vreg",
					  "sensor_gpio",
					  "sensor_gpio",
					  "sensor_gpio",
					  "sensor_gpio",
					  "sensor_clk",		
					  "sensor_i2c_mux";
		qcom,cam-power-seq-val =  "cam_vio",
		                          "cam_vana",
					  "sensor_gpio_vana",
					  "cam_vdig",
					  "sensor_gpio_standby",
					  "sensor_gpio_reset",
					  "sensor_gpio_standby",
					  "sensor_gpio_reset",
					  "sensor_cam_mclk",
					  "none";
		qcom,cam-power-seq-cfg-val = <0 0 1 0 0 0 1 1 23880000 0>;
		qcom,cam-power-seq-delay = <1 1 5 1 1 5 5 10 10 0>;
		clocks = <&clock_gcc clk_mclk1_clk_src>,
		         <&clock_gcc clk_gcc_camss_mclk1_clk>;
		clock-names = "cam_src_clk", "cam_clk";
	};
	eeprom10: qcom,eeprom@76 {
		cell-index = <10>;
		reg = <0x76>;
		qcom,eeprom-name = "darling_ov13850_pu3850d";
		compatible = "qcom,eeprom";
		qcom,slave-addr = <0x6c>;
		qcom,cci-master = <0>;
		qcom,num-blocks = <5>;
		qcom,page0 = <1 0x0100 2 0x01 1 1>;
		qcom,poll0 = <0 0x0 2 0 1 1>;
		qcom,mem0 = <0 0x0 2 0 1 0>;
		qcom,page1 = <1 0x5002 2 0x02 1 1>;
		qcom,poll1 = <0 0x0 2 0 1 1>;
		qcom,mem1 = <0 0x0 2 0 1 0>;
		qcom,page2 = <1 0x3d84 2 0xc0 1 1>;
		qcom,poll2 = <0 0x0 2 0 1 1>;
		qcom,mem2 = <0 0x3d00 2 0 1 0>;
		qcom,page3 = <1 0x3d88 2 0x7220 2 1>;
		qcom,poll3 = <0 0x0 2 0 1 1>;
		qcom,mem3 = <0 0x3d00 2 0 1 0>;
		qcom,page4 = <1 0x3d8a 2 0x73be 2 1>;
		qcom,pageen4 = <1 0x3d81 2 0x01 1 5>;
		qcom,poll4 = <0 0x0 2 0 1 1>;
		qcom,mem4 = <414 0x7220 2 0 1 1>;
	
		cam_vdig-supply = <&pm8916_l2>;
		cam_vana-supply = <&pm8916_l17>;
		cam_vio-supply = <&pm8916_l6>;
		cam_vaf-supply = <&pm8916_l10>;
		qcom,cam-vreg-name = "cam_vdig","cam_vana", "cam_vio","cam_vaf";
		qcom,cam-vreg-type = <0 0 0 0>;
		qcom,cam-vreg-min-voltage = <1200000 2850000 1800000 2800000>;
		qcom,cam-vreg-max-voltage = <1200000 2850000 1800000 2800000>;
		qcom,cam-vreg-op-mode = <150000 150000 150000 140000>;	
		pinctrl-names = "cam_default", "cam_suspend";
		pinctrl-0 = <&cam_sensor_mclk0_default
		             &cam_sensor_rear_default>;
		pinctrl-1 = <&cam_sensor_mclk0_sleep &cam_sensor_rear_sleep>;		
		qcom,gpio-no-mux = <0>;	
		gpios = <&msm_gpio 26 0>,
		        <&msm_gpio 35 0>,
		        <&msm_gpio 34 0>,
		        <&msm_gpio 121 0>;
		qcom,gpio-reset = <1>;
		qcom,gpio-standby = <2>;
		qcom,gpio-vana = <3>;
		qcom,gpio-req-tbl-num = <0 1 2 3>;
		qcom,gpio-req-tbl-flags = <1 0 0 0>;
		qcom,gpio-req-tbl-label = "CAMIF_MCLK",
					  "CAM_RESET",
					  "CAM_STANDBY",
					  "CAM_VANA";
		qcom,cam-power-seq-type = "sensor_gpio",
		                          "sensor_gpio",
					  "sensor_vreg",
					  "sensor_vreg",
					  "sensor_vreg",
					  "sensor_gpio",
					  "sensor_gpio",
					  "sensor_gpio",
					  "sensor_gpio",
					  "sensor_clk",		
					  "sensor_i2c_mux";
		qcom,cam-power-seq-val = "sensor_gpio_vana",
					 "sensor_gpio_vana",
					 "cam_vio",
					 "cam_vdig",
					 "cam_vaf",
					 "sensor_gpio_standby",
					 "sensor_gpio_reset",
					 "sensor_gpio_reset",
					 "sensor_gpio_standby",
					 "sensor_cam_mclk",
					 "none";
		qcom,cam-power-seq-cfg-val = <0 1 0 0 0 0 0 1 1 23880000 0>;   
		qcom,cam-power-seq-delay = <5 10 5 5 5 5 5 5 10 10 0>;
		clocks = <&clock_gcc clk_mclk0_clk_src>,
		         <&clock_gcc clk_gcc_camss_mclk0_clk>;
		clock-names = "cam_src_clk", "cam_clk";
	};
	qcom,camera@0 {
		cell-index = <0>;
		compatible = "qcom,camera";
		reg = <0x0>;
		qcom,csiphy-sd-index = <0>;
		qcom,csid-sd-index = <0>;
		qcom,mount-angle = <90>;
		qcom,actuator-src = <&actuator0>;		
		qcom,eeprom-src = <&eeprom0 &eeprom2 &eeprom3 &eeprom4 &eeprom6 &eeprom8 &eeprom10>;
		qcom,led-flash-src = <&led_flash0>;
		cam_vdig-supply = <&pm8916_l2>;
		cam_vana-supply = <&pm8916_l17>;
		cam_vio-supply = <&pm8916_l6>;
		cam_vaf-supply = <&pm8916_l10>;
		qcom,cam-vreg-name = "cam_vdig", "cam_vio", "cam_vana", "cam_vaf";
		qcom,cam-vreg-type = <0 0 0 0>;
		qcom,cam-vreg-min-voltage = <1200000 1800000 2850000 2800000>;
		qcom,cam-vreg-max-voltage = <1200000 1800000 2850000 2800000>;
		qcom,cam-vreg-op-mode = <150000 150000 150000 140000>;
		pinctrl-names = "cam_default", "cam_suspend";
		pinctrl-0 = <&cam_sensor_mclk0_default
		             &cam_sensor_rear_default>;
		pinctrl-1 = <&cam_sensor_mclk0_sleep &cam_sensor_rear_sleep>;
		gpios = <&msm_gpio 26 0>,
			<&msm_gpio 35 0>,
			<&msm_gpio 34 0>,
			<&msm_gpio 10 0>,
			<&msm_gpio 121 0>;			
		qcom,gpio-reset = <1>;
		qcom,gpio-standby = <2>;
		qcom,gpio-cameraid = <3>;
		qcom,gpio-vana = <4>;		
		qcom,gpio-req-tbl-num = <0 1 2 3 4>;
		qcom,gpio-req-tbl-flags = <1 0 0 1 0>;
		qcom,gpio-req-tbl-label = "CAMIF_MCLK",
			                  "CAM_RESET1",
			                  "CAM_STANDBY",
			                  "CAM_ID",
			                  "CAM_VANA";
		qcom,sensor-position = <0>;
		qcom,sensor-mode = <0>;
		qcom,cci-master = <0>;
		qcom,mclk-23880000;
		status = "ok";
		clocks = <&clock_gcc clk_mclk0_clk_src>,
		         <&clock_gcc clk_gcc_camss_mclk0_clk>;
		clock-names = "cam_src_clk", "cam_clk";
	};

	qcom,camera@1 {
		cell-index = <1>;
		compatible = "qcom,camera";
		reg = <0x1>;
		qcom,csiphy-sd-index = <1>;
		qcom,csid-sd-index = <1>;
		qcom,mount-angle = <270>;
		qcom,eeprom-src = <&eeprom1 &eeprom5 &eeprom7 &eeprom9>;
		cam_vdig-supply = <&pm8916_l6>;
		cam_vana-supply = <&pm8916_l17>;
		cam_vio-supply = <&pm8916_l6>;
		qcom,cam-vreg-name = "cam_vdig", "cam_vio", "cam_vana";
		qcom,cam-vreg-type = <0 0 0>;
		qcom,cam-vreg-min-voltage = <1800000 1800000 2850000>;
		qcom,cam-vreg-max-voltage = <1800000 1800000 2850000>;
		qcom,cam-vreg-op-mode = <150000 150000 150000>;
		pinctrl-names = "cam_default", "cam_suspend";
		pinctrl-0 = <&cam_sensor_mclk1_default &cam_sensor_front_default>;
		pinctrl-1 = <&cam_sensor_mclk1_sleep &cam_sensor_front_sleep>;
		gpios = <&msm_gpio 27 0>,
			<&msm_gpio 28 0>,
			<&msm_gpio 33 0>,
			<&msm_gpio 52 0>,
			<&msm_gpio 121 0>;
		qcom,gpio-reset = <1>;
		qcom,gpio-standby = <2>;
		qcom,gpio-cameraid = <3>;
		qcom,gpio-vana = <4>;			
		qcom,gpio-req-tbl-num = <0 1 2 3 4>;
		qcom,gpio-req-tbl-flags = <1 0 0 1 0>;
		qcom,gpio-req-tbl-label = "CAMIF_MCLK",
			                  "CAM_RESET",
			                  "CAM_STANDBY",
			                  "CAM_ID",
			                  "CAM_VANA";			
		qcom,sensor-position = <1>;
		qcom,sensor-mode = <0>;
		qcom,cci-master = <0>;
		qcom,mclk-23880000;
		status = "ok";
		clocks = <&clock_gcc clk_mclk1_clk_src>,
		         <&clock_gcc clk_gcc_camss_mclk1_clk>;
		clock-names = "cam_src_clk", "cam_clk";
	};
};
